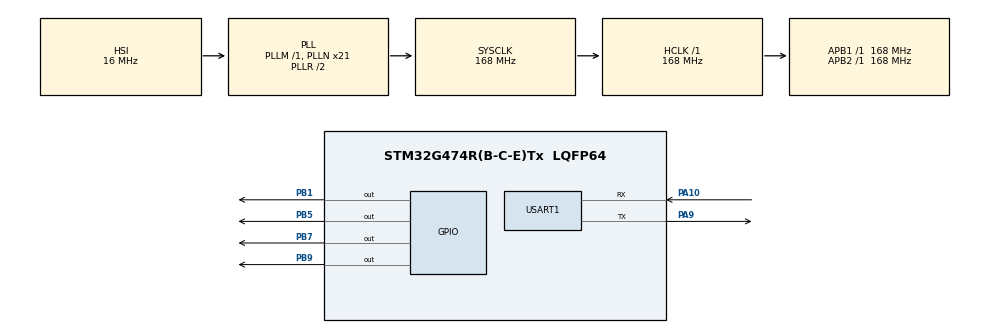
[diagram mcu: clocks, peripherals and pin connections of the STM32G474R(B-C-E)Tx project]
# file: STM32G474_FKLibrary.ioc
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Mcu.Family=STM32G4
Mcu.Name=STM32G474R(B-C-E)Tx
Mcu.Package=LQFP64
NVIC.PriorityGroup=NVIC_PRIORITYGROUP_4
NVIC.TIM3_IRQn=true\:0\:0\:false\:false\:true\:true\:true\:true
NVIC.TIM4_IRQn=true\:0\:0\:false\:false\:true\:true\:true\:true
NVIC.USART1_IRQn=true\:0\:0\:false\:false\:true\:true\:true\:true
PA10.Mode=Asynchronous
PA10.Signal=USART1_RX
PA9.Mode=Asynchronous
PA9.Signal=USART1_TX
PB1.Signal=GPIO_Output
PB5.Signal=GPIO_Output
PB7.Signal=GPIO_Output
PB9.GPIO_Speed=GPIO_SPEED_FREQ_VERY_HIGH
PB9.Signal=GPIO_Output
ProjectManager.HeapSize=0x200
ProjectManager.StackSize=0x400
ProjectManager.TargetToolchain=EWARM V8
RCC.ADC12Freq_Value=168000000
RCC.ADC345Freq_Value=168000000
RCC.AHBFreq_Value=168000000
RCC.APB1Freq_Value=168000000
RCC.APB1TimFreq_Value=168000000
RCC.APB2Freq_Value=168000000
RCC.APB2TimFreq_Value=168000000
RCC.CortexFreq_Value=168000000
RCC.EXTERNAL_CLOCK_VALUE=12288000
RCC.HCLKFreq_Value=168000000
RCC.HSE_VALUE=8000000
RCC.HSI48_VALUE=48000000
RCC.HSI_VALUE=16000000
RCC.LSE_VALUE=32768
RCC.PLLN=21
RCC.SYSCLKFreq_VALUE=168000000
RCC.SYSCLKSource=RCC_SYSCLKSOURCE_PLLCLK
RCC.USBFreq_Value=168000000
RCC.VCOOutputFreq_Value=336000000
TIM3.AutoReloadPreload=TIM_AUTORELOAD_PRELOAD_ENABLE
TIM3.CounterMode=TIM_COUNTERMODE_DOWN
TIM3.PeriodNoDither=10
TIM3.Prescaler=16800-1
TIM4.AutoReloadPreload=TIM_AUTORELOAD_PRELOAD_ENABLE
TIM4.CounterMode=TIM_COUNTERMODE_DOWN
TIM4.PeriodNoDither=1
TIM4.Prescaler=32000-1
USART1.VirtualMode-Asynchronous=VM_ASYNC
VP_SYS_VS_DBSignals.Mode=DisableDeadBatterySignals
VP_TIM3_VS_ClockSourceINT.Mode=Internal
VP_TIM4_VS_ClockSourceINT.Mode=Internal
board=custom

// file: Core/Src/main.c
/* USER CODE BEGIN Header */
/**
  ******************************************************************************
  * @file           : main.c
  * @brief          : Main program body
  ******************************************************************************
  * @attention
  *
  * Copyright (c) 2023 STMicroelectronics.
  * All rights reserved.
  *
  * This software is licensed under terms that can be found in the LICENSE file
  * in the root directory of this software component.
  * If no LICENSE file comes with this software, it is provided AS-IS.
  *
  ******************************************************************************
  */
/* USER CODE END Header */
#include "main.h"

TIM_HandleTypeDef htim3;
TIM_HandleTypeDef htim4;

UART_HandleTypeDef huart1;

void SystemClock_Config(void);
static void MX_GPIO_Init(void);
static void MX_TIM3_Init(void);
static void MX_TIM4_Init(void);
static void MX_USART1_UART_Init(void);

int main(void)
{

  /* MCU Configuration--------------------------------------------------------*/

  /* Reset of all peripherals, Initializes the Flash interface and the Systick. */
  HAL_Init();

  /* Configure the system clock */
  SystemClock_Config();

  /* Initialize all configured peripherals */
  MX_GPIO_Init();
  MX_TIM3_Init();
  MX_TIM4_Init();
  MX_USART1_UART_Init();
  /* USER CODE BEGIN 2 */
  fk_usart1=huart1;
  fk_tim4=htim4;
  fk_tim3=htim3;
  PFC_INIT_API();
  HBTC_INIT_API();
  MODBUS_SLAVE_INIT_API();
  CRC_INIT_API();
  /* USER CODE END 2 */

  /* Infinite loop */
  while (1)
  {

  }
}

void SystemClock_Config(void)
{
  RCC_OscInitTypeDef RCC_OscInitStruct = {0};
  RCC_ClkInitTypeDef RCC_ClkInitStruct = {0};

  /** Configure the main internal regulator output voltage
  */
  HAL_PWREx_ControlVoltageScaling(PWR_REGULATOR_VOLTAGE_SCALE1_BOOST);

  /** Initializes the RCC Oscillators according to the specified parameters
  * in the RCC_OscInitTypeDef structure.
  */
  RCC_OscInitStruct.OscillatorType = RCC_OSCILLATORTYPE_HSI;
  RCC_OscInitStruct.HSIState = RCC_HSI_ON;
  RCC_OscInitStruct.HSICalibrationValue = RCC_HSICALIBRATION_DEFAULT;
  RCC_OscInitStruct.PLL.PLLState = RCC_PLL_ON;
  RCC_OscInitStruct.PLL.PLLSource = RCC_PLLSOURCE_HSI;
  RCC_OscInitStruct.PLL.PLLM = RCC_PLLM_DIV1;
  RCC_OscInitStruct.PLL.PLLN = 21;
  RCC_OscInitStruct.PLL.PLLP = RCC_PLLP_DIV2;
  RCC_OscInitStruct.PLL.PLLQ = RCC_PLLQ_DIV2;
  RCC_OscInitStruct.PLL.PLLR = RCC_PLLR_DIV2;
  if (HAL_RCC_OscConfig(&RCC_OscInitStruct) != HAL_OK)
  {
    Error_Handler();
  }

  /** Initializes the CPU, AHB and APB buses clocks
  */
  RCC_ClkInitStruct.ClockType = RCC_CLOCKTYPE_HCLK|RCC_CLOCKTYPE_SYSCLK
                              |RCC_CLOCKTYPE_PCLK1|RCC_CLOCKTYPE_PCLK2;
  RCC_ClkInitStruct.SYSCLKSource = RCC_SYSCLKSOURCE_PLLCLK;
  RCC_ClkInitStruct.AHBCLKDivider = RCC_SYSCLK_DIV1;
  RCC_ClkInitStruct.APB1CLKDivider = RCC_HCLK_DIV1;
  RCC_ClkInitStruct.APB2CLKDivider = RCC_HCLK_DIV1;

  if (HAL_RCC_ClockConfig(&RCC_ClkInitStruct, FLASH_LATENCY_4) != HAL_OK)
  {
    Error_Handler();
  }
}

static void MX_TIM3_Init(void)
{

  TIM_ClockConfigTypeDef sClockSourceConfig = {0};
  TIM_MasterConfigTypeDef sMasterConfig = {0};

  htim3.Instance = TIM3;
  htim3.Init.Prescaler = 16800-1;
  htim3.Init.CounterMode = TIM_COUNTERMODE_DOWN;
  htim3.Init.Period = 10;
  htim3.Init.ClockDivision = TIM_CLOCKDIVISION_DIV1;
  htim3.Init.AutoReloadPreload = TIM_AUTORELOAD_PRELOAD_ENABLE;
  if (HAL_TIM_Base_Init(&htim3) != HAL_OK)
  {
    Error_Handler();
  }
  sClockSourceConfig.ClockSource = TIM_CLOCKSOURCE_INTERNAL;
  if (HAL_TIM_ConfigClockSource(&htim3, &sClockSourceConfig) != HAL_OK)
  {
    Error_Handler();
  }
  sMasterConfig.MasterOutputTrigger = TIM_TRGO_RESET;
  sMasterConfig.MasterSlaveMode = TIM_MASTERSLAVEMODE_DISABLE;
  if (HAL_TIMEx_MasterConfigSynchronization(&htim3, &sMasterConfig) != HAL_OK)
  {
    Error_Handler();
  }

}

static void MX_TIM4_Init(void)
{

  TIM_ClockConfigTypeDef sClockSourceConfig = {0};
  TIM_MasterConfigTypeDef sMasterConfig = {0};

  htim4.Instance = TIM4;
  htim4.Init.Prescaler = 32000-1;
  htim4.Init.CounterMode = TIM_COUNTERMODE_DOWN;
  htim4.Init.Period = 1;
  htim4.Init.ClockDivision = TIM_CLOCKDIVISION_DIV1;
  htim4.Init.AutoReloadPreload = TIM_AUTORELOAD_PRELOAD_ENABLE;
  if (HAL_TIM_Base_Init(&htim4) != HAL_OK)
  {
    Error_Handler();
  }
  sClockSourceConfig.ClockSource = TIM_CLOCKSOURCE_INTERNAL;
  if (HAL_TIM_ConfigClockSource(&htim4, &sClockSourceConfig) != HAL_OK)
  {
    Error_Handler();
  }
  sMasterConfig.MasterOutputTrigger = TIM_TRGO_RESET;
  sMasterConfig.MasterSlaveMode = TIM_MASTERSLAVEMODE_DISABLE;
  if (HAL_TIMEx_MasterConfigSynchronization(&htim4, &sMasterConfig) != HAL_OK)
  {
    Error_Handler();
  }

}

static void MX_USART1_UART_Init(void)
{

  huart1.Instance = USART1;
  huart1.Init.BaudRate = 115200;
  huart1.Init.WordLength = UART_WORDLENGTH_8B;
  huart1.Init.StopBits = UART_STOPBITS_1;
  huart1.Init.Parity = UART_PARITY_NONE;
  huart1.Init.Mode = UART_MODE_TX_RX;
  huart1.Init.HwFlowCtl = UART_HWCONTROL_NONE;
  huart1.Init.OverSampling = UART_OVERSAMPLING_16;
  huart1.Init.OneBitSampling = UART_ONE_BIT_SAMPLE_DISABLE;
  huart1.Init.ClockPrescaler = UART_PRESCALER_DIV1;
  huart1.AdvancedInit.AdvFeatureInit = UART_ADVFEATURE_NO_INIT;
  if (HAL_UART_Init(&huart1) != HAL_OK)
  {
    Error_Handler();
  }
  if (HAL_UARTEx_SetTxFifoThreshold(&huart1, UART_TXFIFO_THRESHOLD_1_8) != HAL_OK)
  {
    Error_Handler();
  }
  if (HAL_UARTEx_SetRxFifoThreshold(&huart1, UART_RXFIFO_THRESHOLD_1_8) != HAL_OK)
  {
    Error_Handler();
  }
  if (HAL_UARTEx_DisableFifoMode(&huart1) != HAL_OK)
  {
    Error_Handler();
  }

}

static void MX_GPIO_Init(void)
{
  GPIO_InitTypeDef GPIO_InitStruct = {0};

  /* GPIO Ports Clock Enable */
  __HAL_RCC_GPIOB_CLK_ENABLE();
  __HAL_RCC_GPIOA_CLK_ENABLE();

  /*Configure GPIO pin Output Level */
  HAL_GPIO_WritePin(GPIOB, GPIO_PIN_1|GPIO_PIN_5|GPIO_PIN_7|GPIO_PIN_9, GPIO_PIN_RESET);

  /*Configure GPIO pins : PB1 PB5 PB7 */
  GPIO_InitStruct.Pin = GPIO_PIN_1|GPIO_PIN_5|GPIO_PIN_7;
  GPIO_InitStruct.Mode = GPIO_MODE_OUTPUT_PP;
  GPIO_InitStruct.Pull = GPIO_NOPULL;
  GPIO_InitStruct.Speed = GPIO_SPEED_FREQ_LOW;
  HAL_GPIO_Init(GPIOB, &GPIO_InitStruct);

  /*Configure GPIO pin : PB9 */
  GPIO_InitStruct.Pin = GPIO_PIN_9;
  GPIO_InitStruct.Mode = GPIO_MODE_OUTPUT_PP;
  GPIO_InitStruct.Pull = GPIO_NOPULL;
  GPIO_InitStruct.Speed = GPIO_SPEED_FREQ_VERY_HIGH;
  HAL_GPIO_Init(GPIOB, &GPIO_InitStruct);

}

void Error_Handler(void)
{
  __disable_irq();
  while (1)
  {
  }
}
